AUTOSAR XML (schema 00048)
package /HuaweiMDC/PlatformApplication/InsCmCenterApplication/Execution
  executable ins_a_cm
    root sw component prototype ins_a_cm: application-type=ins_a_cm
package /HuaweiMDC/PlatformApplication/InsCmCenterApplication/InsCmProcessStartupConfig
  startup config set InsCmStartupConfigSet
    startup config InsCmStartupConfig: scheduling-policy=SCHEDULING-POLICY-ROUND-ROBIN, scheduling-priority=12
package /HuaweiMDC/PlatformApplication/InsCmCenterApplication/SwComponent
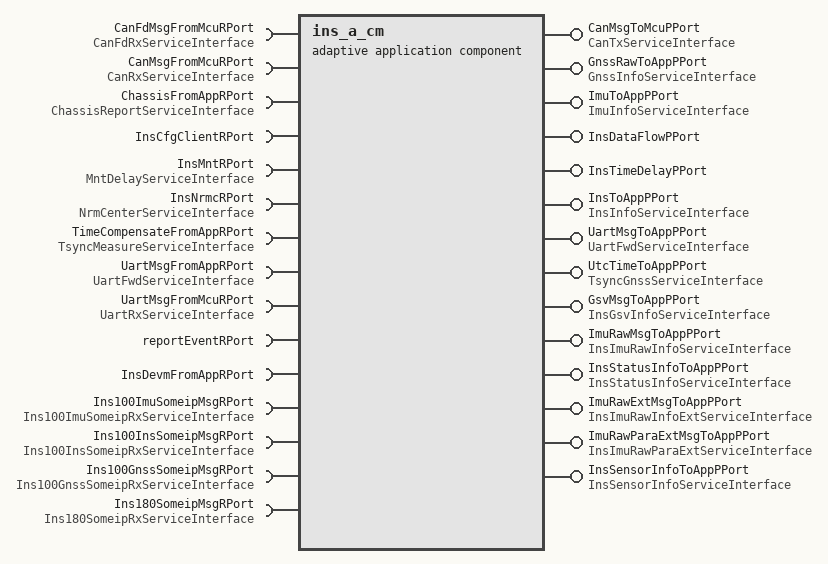
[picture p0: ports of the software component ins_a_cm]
  adaptive application sw component type ins_a_cm
    require port CanFdMsgFromMcuRPort: required-interface=CanFdRxServiceInterface
    require port CanMsgFromMcuRPort: required-interface=CanRxServiceInterface
    provide port CanMsgToMcuPPort: provided-interface=CanTxServiceInterface
    require port ChassisFromAppRPort: required-interface=ChassisReportServiceInterface
    provide port GnssRawToAppPPort: provided-interface=GnssInfoServiceInterface
    provide port ImuToAppPPort: provided-interface=ImuInfoServiceInterface
    require port InsCfgClientRPort
    provide port InsDataFlowPPort
    require port InsMntRPort: required-interface=MntDelayServiceInterface
    require port InsNrmcRPort: required-interface=NrmCenterServiceInterface
    provide port InsTimeDelayPPort
    provide port InsToAppPPort: provided-interface=InsInfoServiceInterface
    require port TimeCompensateFromAppRPort: required-interface=TsyncMeasureServiceInterface
    require port UartMsgFromAppRPort: required-interface=UartFwdServiceInterface
    require port UartMsgFromMcuRPort: required-interface=UartRxServiceInterface
    provide port UartMsgToAppPPort: provided-interface=UartFwdServiceInterface
    provide port UtcTimeToAppPPort: provided-interface=TsyncGnssServiceInterface
    require port reportEventRPort
    provide port GsvMsgToAppPPort: provided-interface=InsGsvInfoServiceInterface
    require port InsDevmFromAppRPort
    provide port ImuRawMsgToAppPPort: provided-interface=InsImuRawInfoServiceInterface
    provide port InsStatusInfoToAppPPort: provided-interface=InsStatusInfoServiceInterface
    4 x require port:
      Ins100ImuSomeipMsgRPort: required-interface=Ins100ImuSomeipRxServiceInterface
      Ins100InsSomeipMsgRPort: required-interface=Ins100InsSomeipRxServiceInterface
      Ins100GnssSomeipMsgRPort: required-interface=Ins100GnssSomeipRxServiceInterface
      Ins180SomeipMsgRPort: required-interface=Ins180SomeipRxServiceInterface
    provide port ImuRawExtMsgToAppPPort: provided-interface=InsImuRawInfoExtServiceInterface
    provide port ImuRawParaExtMsgToAppPPort: provided-interface=InsImuRawParaExtServiceInterface
    provide port InsSensorInfoToAppPPort: provided-interface=InsSensorInfoServiceInterface
  composition sw component type ins_a
    component diag_agent: type=diag_agent
    component ins_a_cm: type=ins_a_cm
